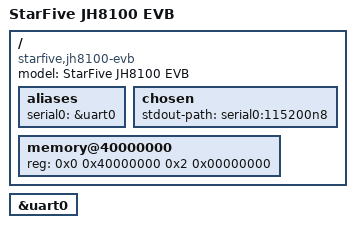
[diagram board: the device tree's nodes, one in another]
// SPDX-License-Identifier: GPL-2.0 OR MIT
/*
 * Copyright (c) 2021-2023 StarFive Technology Co., Ltd.
 */

#include "jh8100.dtsi"

/ {
	model = "StarFive JH8100 EVB";
	compatible = "starfive,jh8100-evb", "starfive,jh8100";

	aliases {
		serial0 = &uart0;
	};

	chosen {
		stdout-path = "serial0:115200n8";
	};

	memory@40000000 {
		device_type = "memory";
		reg = <0x0 0x40000000 0x2 0x00000000>;
	};
};

&uart0 {
	status = "okay";
};
